# RockChip_RK3588 register map
Vendor: RockChip Electronics Co., Ltd.; Series: RK3588; File version: 0.1
Registers are 32-bit, read-write, no defined reset value unless marked. A register's access mark holds for its fields unless they carry their own. Offsets are from the block's base; [hi:lo] are bit positions; 'fields as' and 'values as' point back to an identical list.

## CRU_PMU1
Base 0xFD7F0000
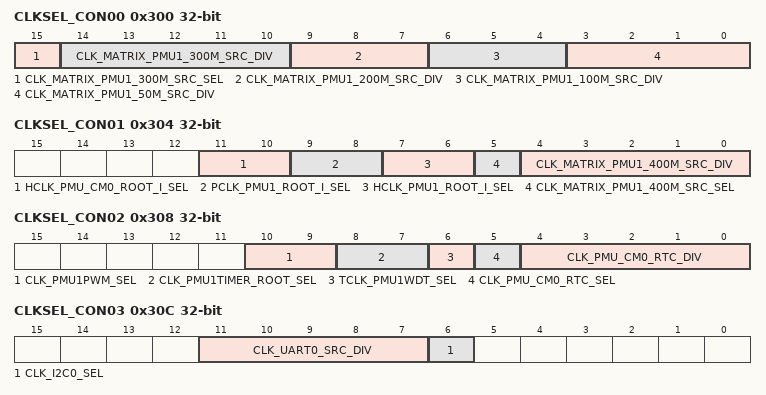
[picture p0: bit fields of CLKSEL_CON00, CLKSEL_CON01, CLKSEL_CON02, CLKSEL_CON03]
0x300 CLKSEL_CON00 — Internal clock select and division register 0
  [15] CLK_MATRIX_PMU1_300M_SRC_SEL — clk_matrix_pmu1_300m_src clock mux.
    0=CLK_MATRIX_300M_SRC; 1=XIN_OSC0_FUNC
  [14:10] CLK_MATRIX_PMU1_300M_SRC_DIV — Divide clk_matrix_pmu1_300m_src by (div_con + 1).
  [9:7] CLK_MATRIX_PMU1_200M_SRC_DIV — Divide clk_matrix_pmu1_200m_src by (div_con + 1).
  [6:4] CLK_MATRIX_PMU1_100M_SRC_DIV — Divide clk_matrix_pmu1_100m_src by (div_con + 1).
  [3:0] CLK_MATRIX_PMU1_50M_SRC_DIV — Divide clk_matrix_pmu1_50m_src by (div_con + 1).
0x304 CLKSEL_CON01 — Internal clock select and division register 1
  [11:10] HCLK_PMU_CM0_ROOT_I_SEL — hclk_pmu_cm0_root_i clock mux.
    0=CLK_MATRIX_PMU1_400M_SRC; 1=CLK_MATRIX_PMU1_200M_SRC; 2=CLK_MATRIX_PMU1_100M_SRC; 3=XIN_OSC0_FUNC
  [9:8] PCLK_PMU1_ROOT_I_SEL — pclk_pmu1_root_i clock mux.
    0=CLK_MATRIX_PMU1_100M_SRC; 1=CLK_MATRIX_PMU1_50M_SRC; 2=XIN_OSC0_FUNC
  [7:6] HCLK_PMU1_ROOT_I_SEL — hclk_pmu1_root_i clock mux.
    0=CLK_MATRIX_PMU1_200M_SRC; 1=CLK_MATRIX_PMU1_100M_SRC; 2=CLK_MATRIX_PMU1_50M_SRC; 3=XIN_OSC0_FUNC
  [5] CLK_MATRIX_PMU1_400M_SRC_SEL — clk_matrix_pmu1_400m_src clock mux.
    0=CLK_MATRIX_400M_SRC; 1=XIN_OSC0_FUNC
  [4:0] CLK_MATRIX_PMU1_400M_SRC_DIV — Divide clk_matrix_pmu1_400m_src by (div_con + 1).
0x308 CLKSEL_CON02 — Internal clock select and division register 2
  [10:9] CLK_PMU1PWM_SEL — clk_pmu1pwm clock mux.
    values as CLKSEL_CON01.PCLK_PMU1_ROOT_I_SEL
  [8:7] CLK_PMU1TIMER_ROOT_SEL — clk_pmu1timer_root clock mux.
    0=XIN_OSC0_FUNC; 1=CLK_DEEPSLOW; 2=CLK_MATRIX_PMU1_100M_SRC
  [6] TCLK_PMU1WDT_SEL — tclk_pmu1wdt clock mux.
    0=XIN_OSC0_FUNC; 1=CLK_DEEPSLOW
  [5] CLK_PMU_CM0_RTC_SEL — clk_pmu_cm0_rtc clock mux.
    0=XIN_OSC0_FUNC; 1=CLK_DEEPSLOW
  [4:0] CLK_PMU_CM0_RTC_DIV — Divide clk_pmu_cm0_rtc by (div_con + 1).
0x30C CLKSEL_CON03 — Internal clock select and division register 3
  [11:7] CLK_UART0_SRC_DIV — Divide clk_uart0_src by (div_con + 1).
  [6] CLK_I2C0_SEL — clk_i2c0 clock mux.
    0=CLK_MATRIX_PMU1_200M_SRC; 1=CLK_MATRIX_PMU1_100M_SRC
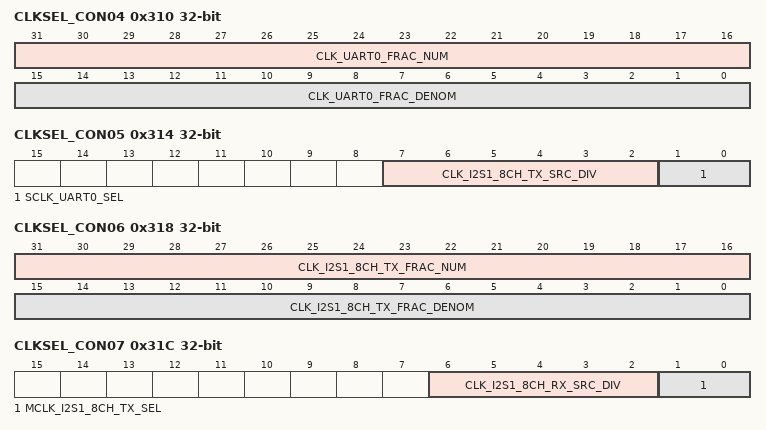
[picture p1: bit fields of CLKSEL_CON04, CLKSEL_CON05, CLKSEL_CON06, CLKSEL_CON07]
0x310 CLKSEL_CON04 — Internal clock select and division register 4
  [31:16] CLK_UART0_FRAC_NUM — clk_uart0_frac fraction division register. High 16-bit for numerator.
  [15:0] CLK_UART0_FRAC_DENOM — clk_uart0_frac fraction division register. Low 16-bit for denominator.
0x314 CLKSEL_CON05 — Internal clock select and division register 5
  [7:2] CLK_I2S1_8CH_TX_SRC_DIV — Divide clk_i2s1_8ch_tx_src by (div_con + 1).
  [1:0] SCLK_UART0_SEL — sclk_uart0 clock mux.
    0=CLK_UART0_SRC; 1=CLK_UART0_FRAC; 2=XIN_OSC0_FUNC
0x318 CLKSEL_CON06 — Internal clock select and division register 6
  [31:16] CLK_I2S1_8CH_TX_FRAC_NUM — clk_i2s1_8ch_tx_frac fraction division register. High 16-bit for numerator.
  [15:0] CLK_I2S1_8CH_TX_FRAC_DENOM — clk_i2s1_8ch_tx_frac fraction division register. Low 16-bit for denominator.
0x31C CLKSEL_CON07 — Internal clock select and division register 7
  [6:2] CLK_I2S1_8CH_RX_SRC_DIV — Divide clk_i2s1_8ch_rx_src by (div_con + 1).
  [1:0] MCLK_I2S1_8CH_TX_SEL — mclk_i2s1_8ch_tx clock mux.
    0=CLK_I2S1_8CH_TX_SRC; 1=CLK_I2S1_8CH_TX_FRAC; 2=I2S1_MCLKIN; 3=XIN_OSC0_HALF
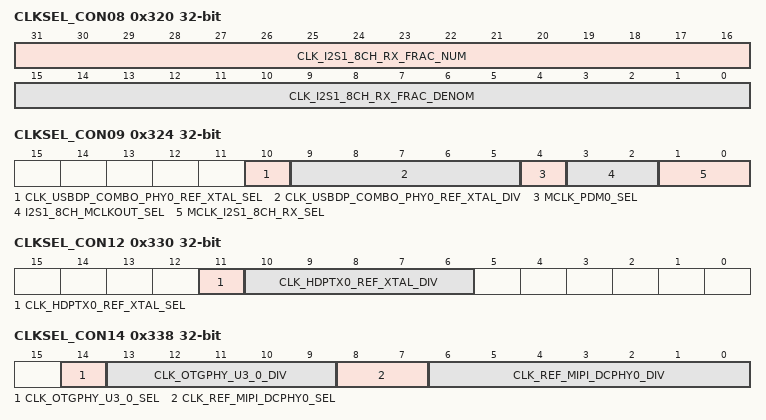
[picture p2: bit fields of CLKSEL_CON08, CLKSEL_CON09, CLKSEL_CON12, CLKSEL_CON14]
0x320 CLKSEL_CON08 — Internal clock select and division register 8
  [31:16] CLK_I2S1_8CH_RX_FRAC_NUM — clk_i2s1_8ch_rx_frac fraction division register. High 16-bit for numerator.
  [15:0] CLK_I2S1_8CH_RX_FRAC_DENOM — clk_i2s1_8ch_rx_frac fraction division register. Low 16-bit for denominator.
0x324 CLKSEL_CON09 — Internal clock select and division register 9
  [10] CLK_USBDP_COMBO_PHY0_REF_XTAL_SEL — clk_usbdp_combo_phy0_ref_xtal clock mux.
    0=XIN_OSC0_FUNC; 1=CLK_PPLL
  [9:5] CLK_USBDP_COMBO_PHY0_REF_XTAL_DIV — Divide clk_usbdp_combo_phy0_ref_xtal by (div_con + 1).
  [4] MCLK_PDM0_SEL — mclk_pdm0 clock mux.
    0=CLK_MATRIX_PMU1_300M_SRC; 1=CLK_MATRIX_PMU1_200M_SRC
  [3:2] I2S1_8CH_MCLKOUT_SEL — i2s1_8ch_mclkout clock mux.
    0=MCLK_I2S1_8CH_TX; 1=MCLK_I2S1_8CH_RX; 2=XIN_OSC0_HALF
  [1:0] MCLK_I2S1_8CH_RX_SEL — mclk_i2s1_8ch_rx clock mux.
    0=CLK_I2S1_8CH_RX_SRC; 1=CLK_I2S1_8CH_RX_FRAC; 2=I2S1_MCLKIN; 3=XIN_OSC0_HALF
0x330 CLKSEL_CON12 — Internal clock select and division register 12
  [11] CLK_HDPTX0_REF_XTAL_SEL — clk_hdptx0_ref_xtal clock mux.
    0=XIN_OSC0_FUNC; 1=CLK_PPLL
  [10:6] CLK_HDPTX0_REF_XTAL_DIV — Divide clk_hdptx0_ref_xtal by (div_con + 1).
0x338 CLKSEL_CON14 — Internal clock select and division register 14
  [14] CLK_OTGPHY_U3_0_SEL — clk_otgphy_u3_0 clock mux.
    0=XIN_OSC0_FUNC; 1=CLK_PPLL
  [13:9] CLK_OTGPHY_U3_0_DIV — Divide clk_otgphy_u3_0 by (div_con + 1).
  [8:7] CLK_REF_MIPI_DCPHY0_SEL — clk_ref_mipi_dcphy0 clock mux.
    0=XIN_OSC0_FUNC; 1=CLK_PPLL; 2=CLK_SPLL_MUX
  [6:0] CLK_REF_MIPI_DCPHY0_DIV — Divide clk_ref_mipi_dcphy0 by (div_con + 1).
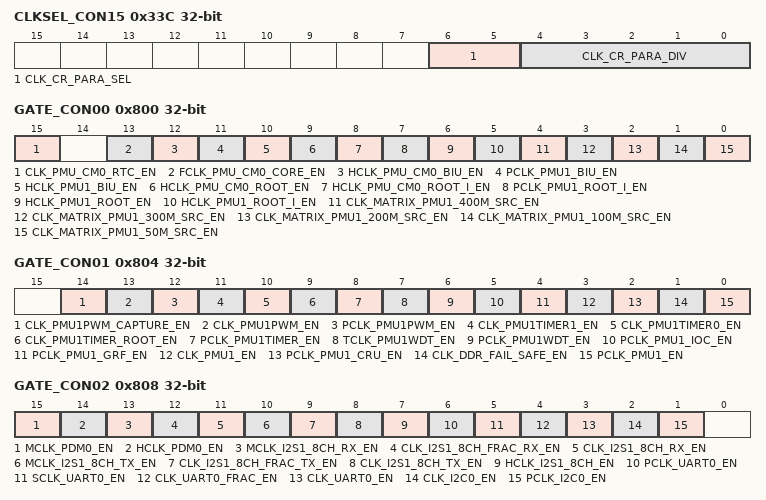
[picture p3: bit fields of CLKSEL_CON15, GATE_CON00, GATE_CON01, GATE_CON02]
0x33C CLKSEL_CON15 — Internal clock select and division register 15
  [6:5] CLK_CR_PARA_SEL — clk_cr_para clock mux.
    0=XIN_OSC0_FUNC; 1=CLK_PPLL; 2=CLK_SPLL_MUX
  [4:0] CLK_CR_PARA_DIV — Divide clk_cr_para by (div_con + 1).
0x344 CLKSEL_CON17 — Internal clock select and division register 17
  [0] DBCLK_GPIO0_SEL — dbclk_gpio0 clock mux.
    0=XIN_OSC0_FUNC; 1=CLK_DEEPSLOW
0x800 GATE_CON00 — Internal clock gate and division register 0
  [all] fields
    0=ENABLE; 1=DISABLE
  [15] CLK_PMU_CM0_RTC_EN — clk_pmu_cm0_rtc clock gating control.
  [13] FCLK_PMU_CM0_CORE_EN — fclk_pmu_cm0_core clock gating control.
  [12] HCLK_PMU_CM0_BIU_EN — hclk_pmu_cm0_biu clock gating control.
  [11] PCLK_PMU1_BIU_EN — pclk_pmu1_biu clock gating control.
  [10] HCLK_PMU1_BIU_EN — hclk_pmu1_biu clock gating control.
  [9] HCLK_PMU_CM0_ROOT_EN — hclk_pmu_cm0_root clock gating control.
  [8] HCLK_PMU_CM0_ROOT_I_EN — hclk_pmu_cm0_root_i clock gating control.
  [7] PCLK_PMU1_ROOT_I_EN — pclk_pmu1_root_i clock gating control.
  [6] HCLK_PMU1_ROOT_EN — hclk_pmu1_root clock gating control.
  [5] HCLK_PMU1_ROOT_I_EN — hclk_pmu1_root_i clock gating control.
  [4] CLK_MATRIX_PMU1_400M_SRC_EN — clk_matrix_pmu1_400m_src clock gating control.
  [3] CLK_MATRIX_PMU1_300M_SRC_EN — clk_matrix_pmu1_300m_src clock gating control.
  [2] CLK_MATRIX_PMU1_200M_SRC_EN — clk_matrix_pmu1_200m_src clock gating control.
  [1] CLK_MATRIX_PMU1_100M_SRC_EN — clk_matrix_pmu1_100m_src clock gating control.
  [0] CLK_MATRIX_PMU1_50M_SRC_EN — clk_matrix_pmu1_50m_src clock gating control.
0x804 GATE_CON01 — Internal clock gate and division register 1
  [all] fields
    0=ENABLE; 1=DISABLE
  [14] CLK_PMU1PWM_CAPTURE_EN — clk_pmu1pwm_capture clock gating control.
  [13] CLK_PMU1PWM_EN — clk_pmu1pwm clock gating control.
  [12] PCLK_PMU1PWM_EN — pclk_pmu1pwm clock gating control.
  [11] CLK_PMU1TIMER1_EN — clk_pmu1timer1 clock gating control.
  [10] CLK_PMU1TIMER0_EN — clk_pmu1timer0 clock gating control.
  [9] CLK_PMU1TIMER_ROOT_EN — clk_pmu1timer_root clock gating control.
  [8] PCLK_PMU1TIMER_EN — pclk_pmu1timer clock gating control.
  [7] TCLK_PMU1WDT_EN — tclk_pmu1wdt clock gating control.
  [6] PCLK_PMU1WDT_EN — pclk_pmu1wdt clock gating control.
  [5] PCLK_PMU1_IOC_EN — pclk_pmu1_ioc clock gating control.
  [4] PCLK_PMU1_GRF_EN — pclk_pmu1_grf clock gating control.
  [3] CLK_PMU1_EN — clk_pmu1 clock gating control.
  [2] PCLK_PMU1_CRU_EN — pclk_pmu1_cru clock gating control.
  [1] CLK_DDR_FAIL_SAFE_EN — clk_ddr_fail_safe clock gating control.
  [0] PCLK_PMU1_EN — pclk_pmu1 clock gating control.
0x808 GATE_CON02 — Internal clock gate and division register 2
  [all] fields
    0=ENABLE; 1=DISABLE
  [15] MCLK_PDM0_EN — mclk_pdm0 clock gating control.
  [14] HCLK_PDM0_EN — hclk_pdm0 clock gating control.
  [13] MCLK_I2S1_8CH_RX_EN — mclk_i2s1_8ch_rx clock gating control.
  [12] CLK_I2S1_8CH_FRAC_RX_EN — clk_i2s1_8ch_rx_frac clock gating control.
  [11] CLK_I2S1_8CH_RX_EN — clk_i2s1_8ch_rx_src clock gating control.
  [10] MCLK_I2S1_8CH_TX_EN — mclk_i2s1_8ch_tx clock gating control.
  [9] CLK_I2S1_8CH_FRAC_TX_EN — clk_i2s1_8ch_tx_frac clock gating control.
  [8] CLK_I2S1_8CH_TX_EN — clk_i2s1_8ch_tx_src clock gating control.
  [7] HCLK_I2S1_8CH_EN — hclk_i2s1_8ch clock gating control.
  [6] PCLK_UART0_EN — pclk_uart0 clock gating control.
  [5] SCLK_UART0_EN — sclk_uart0 clock gating control.
  [4] CLK_UART0_FRAC_EN — clk_uart0_frac clock gating control.
  [3] CLK_UART0_EN — clk_uart0_src clock gating control.
  [2] CLK_I2C0_EN — clk_i2c0 clock gating control.
  [1] PCLK_I2C0_EN — pclk_i2c0 clock gating control.
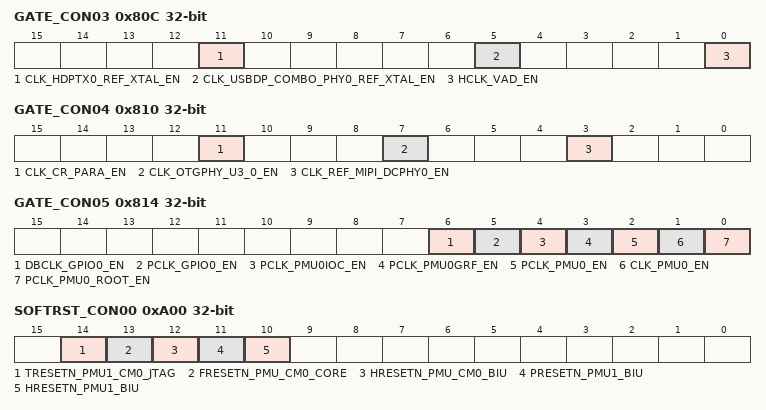
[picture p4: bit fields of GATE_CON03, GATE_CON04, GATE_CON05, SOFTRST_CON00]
0x80C GATE_CON03 — Internal clock gate and division register 3
  [all] fields
    0=ENABLE; 1=DISABLE
  [11] CLK_HDPTX0_REF_XTAL_EN — clk_hdptx0_ref_xtal clock gating control.
  [5] CLK_USBDP_COMBO_PHY0_REF_XTAL_EN — clk_usbdp_combo_phy0_ref_xtal clock gating control.
  [0] HCLK_VAD_EN — hclk_vad clock gating control.
0x810 GATE_CON04 — Internal clock gate and division register 4
  [all] fields
    0=ENABLE; 1=DISABLE
  [11] CLK_CR_PARA_EN — clk_cr_para clock gating control.
  [7] CLK_OTGPHY_U3_0_EN — clk_otgphy_u3_0 clock gating control.
  [3] CLK_REF_MIPI_DCPHY0_EN — clk_ref_mipi_dcphy0 clock gating control.
0x814 GATE_CON05 — Internal clock gate and division register 5
  [all] fields
    0=ENABLE; 1=DISABLE
  [6] DBCLK_GPIO0_EN — dbclk_gpio0 clock gating control.
  [5] PCLK_GPIO0_EN — pclk_gpio0 clock gating control.
  [4] PCLK_PMU0IOC_EN — pclk_pmu0ioc clock gating control.
  [3] PCLK_PMU0GRF_EN — pclk_pmu0grf clock gating control.
  [2] PCLK_PMU0_EN — pclk_pmu0 clock gating control.
  [1] CLK_PMU0_EN — clk_pmu0 clock gating control.
  [0] PCLK_PMU0_ROOT_EN — pclk_pmu0_root clock gating control.
0xA00 SOFTRST_CON00 — Internal clock reset register 0
  [14] TRESETN_PMU1_CM0_JTAG — When high, reset relative logic
  [13] FRESETN_PMU_CM0_CORE — When high, reset relative logic
  [12] HRESETN_PMU_CM0_BIU — When high, reset relative logic
  [11] PRESETN_PMU1_BIU — When high, reset relative logic
  [10] HRESETN_PMU1_BIU — When high, reset relative logic
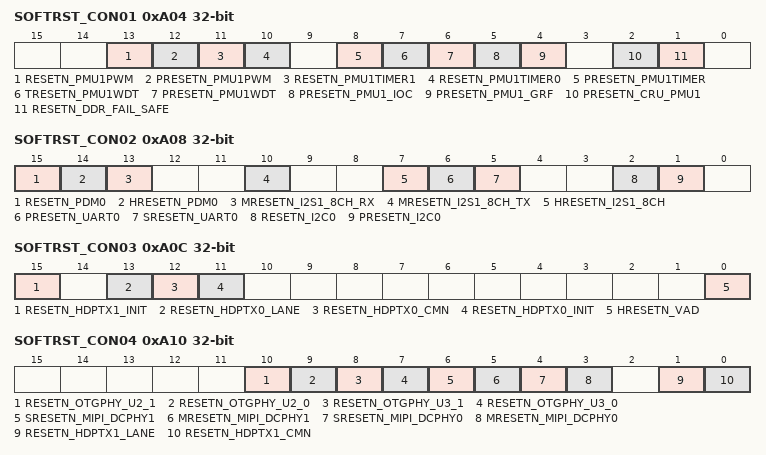
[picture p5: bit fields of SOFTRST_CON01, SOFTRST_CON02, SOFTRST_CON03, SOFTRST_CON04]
0xA04 SOFTRST_CON01 — Internal clock reset register 1
  [13] RESETN_PMU1PWM — When high, reset relative logic
  [12] PRESETN_PMU1PWM — When high, reset relative logic
  [11] RESETN_PMU1TIMER1 — When high, reset relative logic
  [10] RESETN_PMU1TIMER0 — When high, reset relative logic
  [8] PRESETN_PMU1TIMER — When high, reset relative logic
  [7] TRESETN_PMU1WDT — When high, reset relative logic
  [6] PRESETN_PMU1WDT — When high, reset relative logic
  [5] PRESETN_PMU1_IOC — When high, reset relative logic
  [4] PRESETN_PMU1_GRF — When high, reset relative logic
  [2] PRESETN_CRU_PMU1 — When high, reset relative logic
  [1] RESETN_DDR_FAIL_SAFE — When high, reset relative logic
0xA08 SOFTRST_CON02 — Internal clock reset register 2
  [15] RESETN_PDM0 — When high, reset relative logic
  [14] HRESETN_PDM0 — When high, reset relative logic
  [13] MRESETN_I2S1_8CH_RX — When high, reset relative logic
  [10] MRESETN_I2S1_8CH_TX — When high, reset relative logic
  [7] HRESETN_I2S1_8CH — When high, reset relative logic
  [6] PRESETN_UART0 — When high, reset relative logic
  [5] SRESETN_UART0 — When high, reset relative logic
  [2] RESETN_I2C0 — When high, reset relative logic
  [1] PRESETN_I2C0 — When high, reset relative logic
0xA0C SOFTRST_CON03 — Internal clock reset register 3
  [15] RESETN_HDPTX1_INIT — When high, reset relative logic
  [13] RESETN_HDPTX0_LANE — When high, reset relative logic
  [12] RESETN_HDPTX0_CMN — When high, reset relative logic
  [11] RESETN_HDPTX0_INIT — When high, reset relative logic
  [0] HRESETN_VAD — When high, reset relative logic
0xA10 SOFTRST_CON04 — Internal clock reset register 4
  [10] RESETN_OTGPHY_U2_1 — When high, reset relative logic
  [9] RESETN_OTGPHY_U2_0 — When high, reset relative logic
  [8] RESETN_OTGPHY_U3_1 — When high, reset relative logic
  [7] RESETN_OTGPHY_U3_0 — When high, reset relative logic
  [6] SRESETN_MIPI_DCPHY1 — When high, reset relative logic
  [5] MRESETN_MIPI_DCPHY1 — When high, reset relative logic
  [4] SRESETN_MIPI_DCPHY0 — When high, reset relative logic
  [3] MRESETN_MIPI_DCPHY0 — When high, reset relative logic
  [1] RESETN_HDPTX1_LANE — When high, reset relative logic
  [0] RESETN_HDPTX1_CMN — When high, reset relative logic
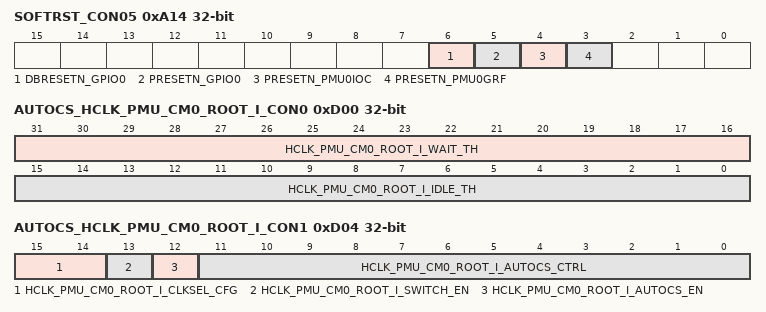
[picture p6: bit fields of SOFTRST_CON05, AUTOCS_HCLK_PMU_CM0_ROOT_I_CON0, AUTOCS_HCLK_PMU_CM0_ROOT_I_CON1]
0xA14 SOFTRST_CON05 — Internal clock reset register 5
  [6] DBRESETN_GPIO0 — When high, reset relative logic
  [5] PRESETN_GPIO0 — When high, reset relative logic
  [4] PRESETN_PMU0IOC — When high, reset relative logic
  [3] PRESETN_PMU0GRF — When high, reset relative logic
0xD00 AUTOCS_HCLK_PMU_CM0_ROOT_I_CON0 — Auto clock switch control register 0
  [31:16] HCLK_PMU_CM0_ROOT_I_WAIT_TH — wait_th. Wait time threshold, measured by original clk.
  [15:0] HCLK_PMU_CM0_ROOT_I_IDLE_TH — idle_th. Idle time threshold, measured by original clk.
0xD04 AUTOCS_HCLK_PMU_CM0_ROOT_I_CON1 — Auto clock switch control register 1
  [15:14] HCLK_PMU_CM0_ROOT_I_CLKSEL_CFG — clksel_cfg Auto switch clock selection.
    0=ORIGINAL_CLK; 1=XIN_OSC0_FUNC_DI1; 2=CLK_RTC_32K
  [13] HCLK_PMU_CM0_ROOT_I_SWITCH_EN — switch_en
    1=ENABLE (Enable hclk_pmu_cm0_root_i switched to lower frequency when module is inactive.); 0=DISABLE (Disable auto switch function.)
  [12] HCLK_PMU_CM0_ROOT_I_AUTOCS_EN — autocs_en
    1=ENABLE (Enable hclk_pmu_cm0_root_i switch to lower frequency.); 0=DISABLE
  [11:0] HCLK_PMU_CM0_ROOT_I_AUTOCS_CTRL — autocs_ctrl. Others: Reserved.
    0xFFF=ENABLE (Enable hclk_pmu_cm0_root_i switch to lower frequency.); 0=DISABLE
